# MCXN947_cm33_core0 register map
Vendor: nxp.com; File version: 1.0
CPU: CM33 r2p0, little endian, MPU, FPU, VTOR, 3 interrupt priority bits
Registers are 32-bit, read-write, reset 0x0 unless marked. A register's access mark holds for its fields unless they carry their own. Offsets are from the block's base; [hi:lo] are bit positions; {n}, {i} and the like mark numbered series.

## TSI0 — TSI
Base 0x40050000
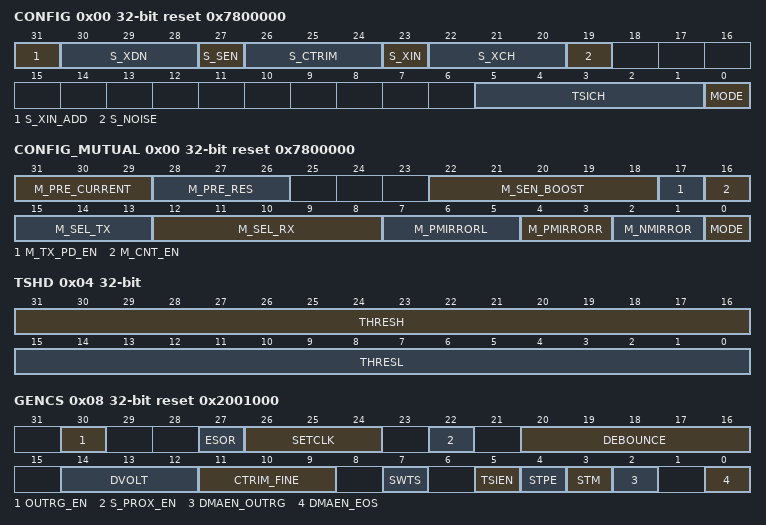
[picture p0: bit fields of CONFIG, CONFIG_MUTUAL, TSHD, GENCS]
0x00 CONFIG reset 0x7800000 (CONFIG view) — TSI CONFIG (TSI_CONFIG) for Self-Capacitor
  [31] S_XIN_ADD — S_XIN Adjust Ratio
    0=Disabled (Disables; S_XIN = 0 for 1 / 4, S_XIN = 1 for 1 / 8); 1=Enabled (Enables; S_XIN = 0 for 1 / 8, S_XIN = 1 for 1 / 16)
  [30:28] S_XDN — Self-Capacitance Discharge Current Multiple
    0=xdn_def_16 (1 / 16); 1=xdn_def_8 (1 / 8); 2=xdn_def_4 (1 / 4); 3=xdn_def_2 (1 / 2)
  [27] S_SEN — Self-Capacitance Sensitivity Boost
    0=Disabled (Disables); 1=Enabled (Enables)
  [26:24] S_CTRIM — Capacitor Trim Setting
    0=ctrim_25 (2.5 pF); 1=ctrim_5 (5.0 pF); 2=ctrim_75 (7.5 pF); 3=ctrim_10 (10 pF); 4=ctrim_125 (12.5 pF); 5=ctrim_15 (15.0 pF); 6=ctrim_175 (17.5 pF); 7=ctrim_20 (20 pF)
  [23] S_XIN — Self-Capacitance Input Current Multiple
    0=xin_def_8 (1 / 8); 1=xin_def_4 (1 / 4)
  [22:20] S_XCH — Self-Capacitance Charge Current Multiple
    0=def_16 (1 / 16); 1=def_8 (1 / 8); 2=def_4 (1 / 4); 3=def_2 (1 / 2)
  [19] S_NOISE — Self-Capacitance Noise Cancelation
    0=Disabled (Disables); 1=Enabled (Enables)
  [5:1] TSICH — TSI Channel
    {v}=self_cp_{v} (Channel {v}) (v=0..24)
  [0] MODE
    0=self_cp (Self capacitance); 1=mtl_cp (Mutual capacitance)
0x00 CONFIG_MUTUAL reset 0x7800000 (CONFIG view) — TSI CONFIG (TSI_CONFIG) for Mutual-Capacitor
  [31:29] M_PRE_CURRENT — Mutual-Capacitance Precharge Current
    {v}=cur_{v+1} ({v+1} uA) (v=0..7)
  [28:26] M_PRE_RES — Mutual-Capacitance Precharge Resistor
    {v}=res_{v+1} ({v+1} k) (v=0..7)
  [22:18] M_SEN_BOOST — Mutual-Capacitance Sensitivity Boost
    0=bst_0 (0 uA); 1=bst_2 (2 uA); 2=bst_4 (4 uA); 3=bst_6 (6 uA); 4=bst_8 (8 uA); 5=bst_10 (10 uA); 6=bst_12 (12 uA); 7=bst_14 (14 uA); 0b1xxxx=bst_2n (2 * n uA)
  [17] M_TX_PD_EN — Mutual-Capacitance TX Pulldown Enable
    0=Disabled (Disables); 1=Enabled (Enables)
  [16] M_CNT_EN — Mutual-Capacitance Counter Enable
    0=Disabled (Disables); 1=Enabled (Enables)
  [15:13] M_SEL_TX — Mutual-Capacitance TX Channel Selection
    {v}=tsi_tx_{v} (TSI[{v}]) (v=0..7)
  [12:8] M_SEL_RX — Mutual-Capacitance RX Channel Selection
    {v}=tsi_{v+8} (v=0..16)
  [7:5] M_PMIRRORL — PMOS Current Mirror on Left Side
    0=mpl4 (m = 4); 1=mpl8 (m = 8); 2=mpl12 (m = 12); 3=mpl16 (m = 16); 4=mpl20 (m = 20); 5=mpl24 (m = 24); 6=mpl28 (m = 28); 7=mpl32 (m = 32)
  [4:3] M_PMIRRORR — PMOS Current Mirror on Right Side
    {v}=mp{v+1} (m = {v+1}) (v=0..3)
  [2:1] M_NMIRROR — NMOS Current Mirror
    {v}=m{v+1} (v=0..3)
  [0] MODE
    0=config_sf_cp (Self capacitance); 1=config_mt_cp (Mutual capacitance)
0x04 TSHD — TSI Threshold
  [31:16] THRESH — TSI Wakeup Channel High Threshold
  [15:0] THRESL — TSI Wakeup Channel Low Threshold
0x08 GENCS reset 0x2001000 — TSI General Control and Status
  [30] OUTRG_EN — Out-of-Range Interrupt Enable
    0=Disabled (Disables); 1=Enabled (Enables)
  [27] ESOR — End-of-Scan Interrupt Enable
    0=Disabled (Disables); 1=Enabled (Enables)
  [26:24] SETCLK — Set Clock
    0=27.37 MHz; 1=22.23 MHz; 2=18.73 MHz; 3=16.65 MHz; 4=14.27 MHz; 5=12.73 MHz; 6=11.49 MHz; 7=10.46 MHz
  [22] S_PROX_EN — Proximity Enable Signal
    0=Disabled (Disables); 1=Enabled (Enables)
  [20:16] DEBOUNCE
    0=int_1 (1); 1=int_2 (2); 0b1xxxx=int_n (n)
  [14:12] DVOLT — Delta Voltage
    0=volt_17 (Vm = 0.6 V, Vp = 1.7 V); 1=volt_19 (Vm = 0.6 V, Vp = 1.9 V); 2=volt_21 (Vm = 0.6 V, Vp = 2.1 V); 3=volt_23 (Vm = 0.6 V, Vp = 2.3 V); 4=volt_25 (Vm = 0.6 V, Vp = 2.5 V); 5=volt_27 (Vm = 0.6 V, Vp = 2.7 V)
  [11:9] CTRIM_FINE — Capacitor Fine Trim
    0=ctrim_3125 (0.3125 pF); 1=ctrim_625 (0.625 pF); {v}=ctrim_{v+31251} (0.3125 * {v+1} pF) (v=2..5); 6=ctrim_1875 (2.1875 pF); 7=ctrim_25 (2.5 pF)
  [7] SWTS — Software Trigger Start
    0=Disabled (No effect); 1=Enabled (Takes effect)
  [5] TSIEN — TSI Enable
    0=Disabled (Disables); 1=Enabled (Enables)
  [4] STPE — TSI Stop Enable
    0=Disabled (Disables); 1=Enabled (Enables)
  [3] STM — Scan Trigger Mode
    0=swtrig_scn (Software trigger scan); 1=hwtrig_scn (Hardware trigger scan)
  [2] DMAEN_OUTRG — Out-of-Range DMA Transfer Request Enable
    0=Disabled (Disables); 1=Enabled (Enables)
  [0] DMAEN_EOS — In-Progress DMA Transfer Request Enable
    0=Disabled (Disables); 1=Enabled (Enables)
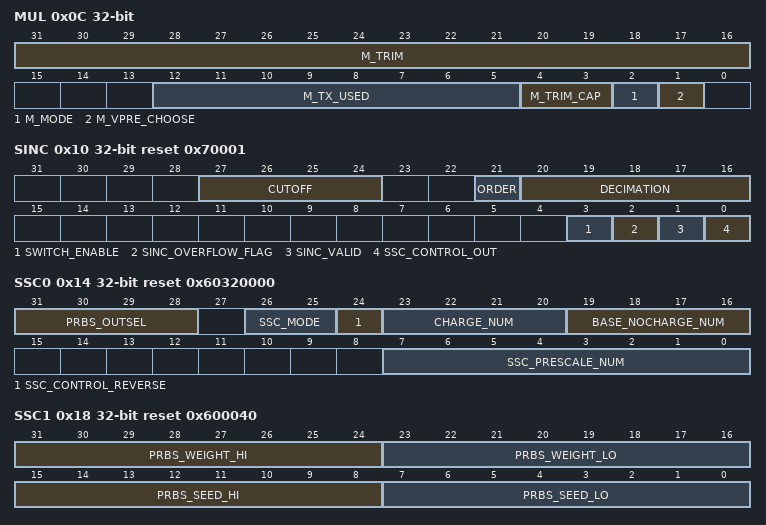
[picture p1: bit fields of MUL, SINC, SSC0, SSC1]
0x0C MUL — TSI Mutual-Capacitance
  [31:16] M_TRIM — Mutual-Capacitance Trim
  [12:5] M_TX_USED — Mutual-Capacitance TX Used
    0=gpio; 1=mtcp (Mutual capacitance)
  [4:3] M_TRIM_CAP — Mutual-Capacitance Trim Cap
    0=cp_0 (0 pF); 1=cp_10 (10 pF); 2=cp_10_1 (10 pF); 3=cp_20 (20 pF)
  [2] M_MODE — Mutual-Capacitance Mode
    0=mode_0 (- 5 V ~ + 5 V); 1=mode_5 (0 V ~ + 5 V)
  [1] M_VPRE_CHOOSE — Mutual-Capacitance Prevoltage
    0=Internal 1.2 V; 1=External 1.2 V from PMC
0x10 SINC reset 0x70001 — TSI SINC Filter
  [27:24] CUTOFF
    0=div_1; 1=div_2; 2=div_4; 3=div_8; 4=div_16; 5=div_32; 6=div_64; 7=div_128; {v}=div_nc{v-7} (Do not use) (v=8..15)
  [21] ORDER
    0=ord_1 (Order 1); 1=ord_2 (Order 2)
  [20:16] DECIMATION
    {v}=dec_{v+1} ({v+1}) (v=0..31)
  [3] SWITCH_ENABLE ro
    0=Disabled; 1=Enabled
  [2] SINC_OVERFLOW_FLAG ro
    0=Disabled (No overflow); 1=Enabled (Overflow)
  [1] SINC_VALID ro
    0=Disabled; 1=Enabled
  [0] SSC_CONTROL_OUT ro — SSC Output Control
    0=Disabled (0); 1=Enabled (1)
0x14 SSC0 reset 0x60320000 — TSI SSC 0
  [31:28] PRBS_OUTSEL — PRBS Output Selection
    0=nc1 (Do not use); 1=nc2 (Do not use); {v}=prbs_{v} ({v}) (v=2..15)
  [26:25] SSC_MODE
    0=PRBS mode; 1=updn (Up-Down Counter mode); 2=Disabled (Disables SSC function); 3=nc (Do not use)
  [24] SSC_CONTROL_REVERSE
    0=Enabled (Polarity retained); 1=Disabled (Polarity reversed)
  [23:20] CHARGE_NUM — Charge Number
    {v}=ssc_{v+1} ({v+1}) (v=0..15)
  [19:16] BASE_NOCHARGE_NUM — Base Nocharge Number
    {v}=ssc_{v+1} ({v+1}) (v=0..15)
  [7:0] SSC_PRESCALE_NUM — SSC Prescale Number
    0=div1; 1=div2; 3=div4; 7=div8; 15=div16; 31=div32; 63=div64; 127=div128; 255=div256
0x18 SSC1 reset 0x600040 — TSI SSC 1
  [31:24] PRBS_WEIGHT_HI — PRBS High Weight
  [23:16] PRBS_WEIGHT_LO — PRBS Low Weight
  [15:8] PRBS_SEED_HI — PRBS High Seed
  [7:0] PRBS_SEED_LO — PRBS Low Seed
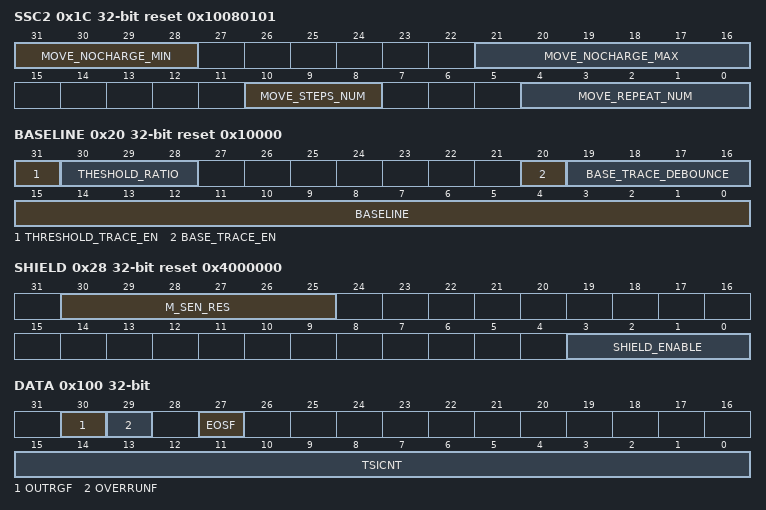
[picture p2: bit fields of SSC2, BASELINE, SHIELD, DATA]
0x1C SSC2 reset 0x10080101 — TSI SSC 2
  [31:28] MOVE_NOCHARGE_MIN — Move Nocharge Minimum
    {v}=mv_{v+1} (({v+1} + SSC0[BASE_NOCHARGE_NUM])) (v=0..15)
  [21:16] MOVE_NOCHARGE_MAX — Move Nocharge Maximum
  [10:8] MOVE_STEPS_NUM — Move Steps Number
    {v}=updn{v} ({v}) (v=0..7)
  [4:0] MOVE_REPEAT_NUM — Move Repeat Number
    {v}=updn_{v+1} ({v+1}) (v=0..6)
0x20 BASELINE reset 0x10000 — TSI Baseline
  [31] THRESHOLD_TRACE_EN — Threshold Trace Enable
    0=Disabled (Disables); 1=Enabled (Enables)
  [30:28] THESHOLD_RATIO — Threshold Ratio
    0=tshd_2 (thresholdh = (baseline + counter) / 2 and thresholdl = (baseline - counter) / 2); 1=tshd_4 (thresholdh = (baseline + counter) / 4 and thresholdl = (baseline - counter) / 4); 2=tshd_8 (thresholdh = (baseline + counter) / 8 and thresholdl = (baseline - counter) / 8); 3=tshd_16 (thresholdh = (baseline + counter) / 16 and thresholdl = (baseline - counter) / 16); 4=tshd_32 (thresholdh = (baseline + counter) / 32 and thresholdl = (baseline - counter) / 32); 5=tshd_64 (thresholdh = (baseline + counter) / 64 and thresholdl = (baseline - counter) / 64); 6=tshd_128 (thresholdh = (baseline + counter) / 128 and thresholdl = (baseline - counter) / 128); 7=tshd_256 (thresholdh = (baseline + counter) / 256 and thresholdl = (baseline - counter) / 256)
  [20] BASE_TRACE_EN — Baseline Trace Enable
  [19:16] BASE_TRACE_DEBOUNCE
    0=ctr_0 (0); 1=ctr_1 (1 / 16); 2=ctr_2 (2 / 16); 3=ctr_3 (3 / 16); 0b1xxx=ctr_n (n / 16)
  [15:0] BASELINE
0x24 CHMERGE — TSI Channel Merge
  [24:0] CHANNEL_ENABLE
    0=Notchosen (Channel not chosen for proximity pad); 1=Chosen (Channel chosen for proximity pad)
0x28 SHIELD reset 0x4000000 — TSI Shield
  [30:25] M_SEN_RES — Mutual-Capacitance Sensitivity Resistor
    0=res_10 (10 k); 1=res_253 (10 k + (2.5 / 3) k (just for auto-calibration)); 2=res_125 (12.5 k (default)); 14=res_25 (25 k)
  [3:0] SHIELD_ENABLE
    0=Disabled (Disables); 1=Enabled (Enables)
0x100 DATA — TSI Data and Status
  [30] OUTRGF — Out-of-Range Flag
  [29] OVERRUNF — Overrun Flag
    0=Disabled (No); 1=Enabled (Yes)
  [27] EOSF — End-of-Scan Flag
  [15:0] TSICNT ro — TSI Conversion Counter Value
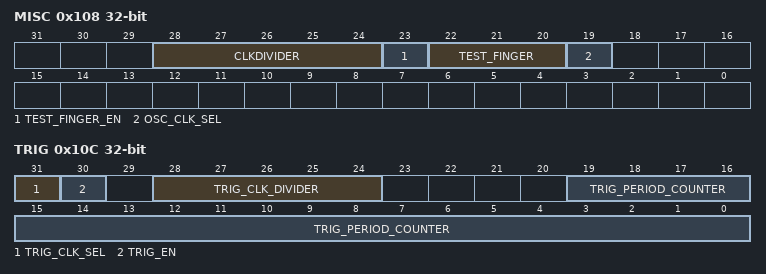
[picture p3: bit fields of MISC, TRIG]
0x108 MISC — TSI Miscellaneous
  [28:24] CLKDIVIDER — TSI Clock Divider
  [23] TEST_FINGER_EN — Test Finger Function Enable Signals
    0=Disabled (Disables); 1=Enabled (Enables)
  [22:20] TEST_FINGER
    0=fin_148 (Finger capacitor is 148 pF); 1=fin_296 (Finger capacitor is 296 pF); 2=fin_444 (Finger capacitor is 444 pF); 3=fin_592 (Finger capacitor is 592 pF); 4=fin_740 (Finger capacitor is 740 pF); 5=fin_888 (Finger capacitor is 888 pF); 6=fin_1036 (Finger capacitor is 1036 pF); 7=fin_1184 (Finger capacitor is 1184 pF)
  [19] OSC_CLK_SEL — Oscillator Clock Select
    0=osc_tsi (Analog oscillator); 1=osc_soc (Chip)
0x10C TRIG — TSI AUTO TRIG
  [31] TRIG_CLK_SEL — Trigger Clock Select
    0=clk_32 (32 k clock); 1=clk_soc
  [30] TRIG_EN — Trigger Enable
    0=Disabled; 1=Enabled
  [28:24] TRIG_CLK_DIVIDER — Trigger Clock Divider
    0=div_no (No divider); 1=div_2 (Divided by 2); 2=div_3 (Divided by 3); 3=div_4 (Divided by 4); 0b1xxxx=div_n (Divided by n)
  [19:0] TRIG_PERIOD_COUNTER — Trigger Period Counter
